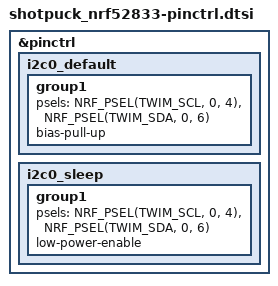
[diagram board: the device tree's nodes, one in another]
/* ShotPuck pin control. Pins chosen from the MDBT50Q bottom pad row. */
&pinctrl {
	i2c0_default: i2c0_default {
		group1 {
			psels = <NRF_PSEL(TWIM_SCL, 0, 4)>,
				<NRF_PSEL(TWIM_SDA, 0, 6)>;
			bias-pull-up;   /* internal pull-ups; external 4.7k DNP pads on PCB */
		};
	};
	i2c0_sleep: i2c0_sleep {
		group1 {
			psels = <NRF_PSEL(TWIM_SCL, 0, 4)>,
				<NRF_PSEL(TWIM_SDA, 0, 6)>;
			low-power-enable;
		};
	};
};
